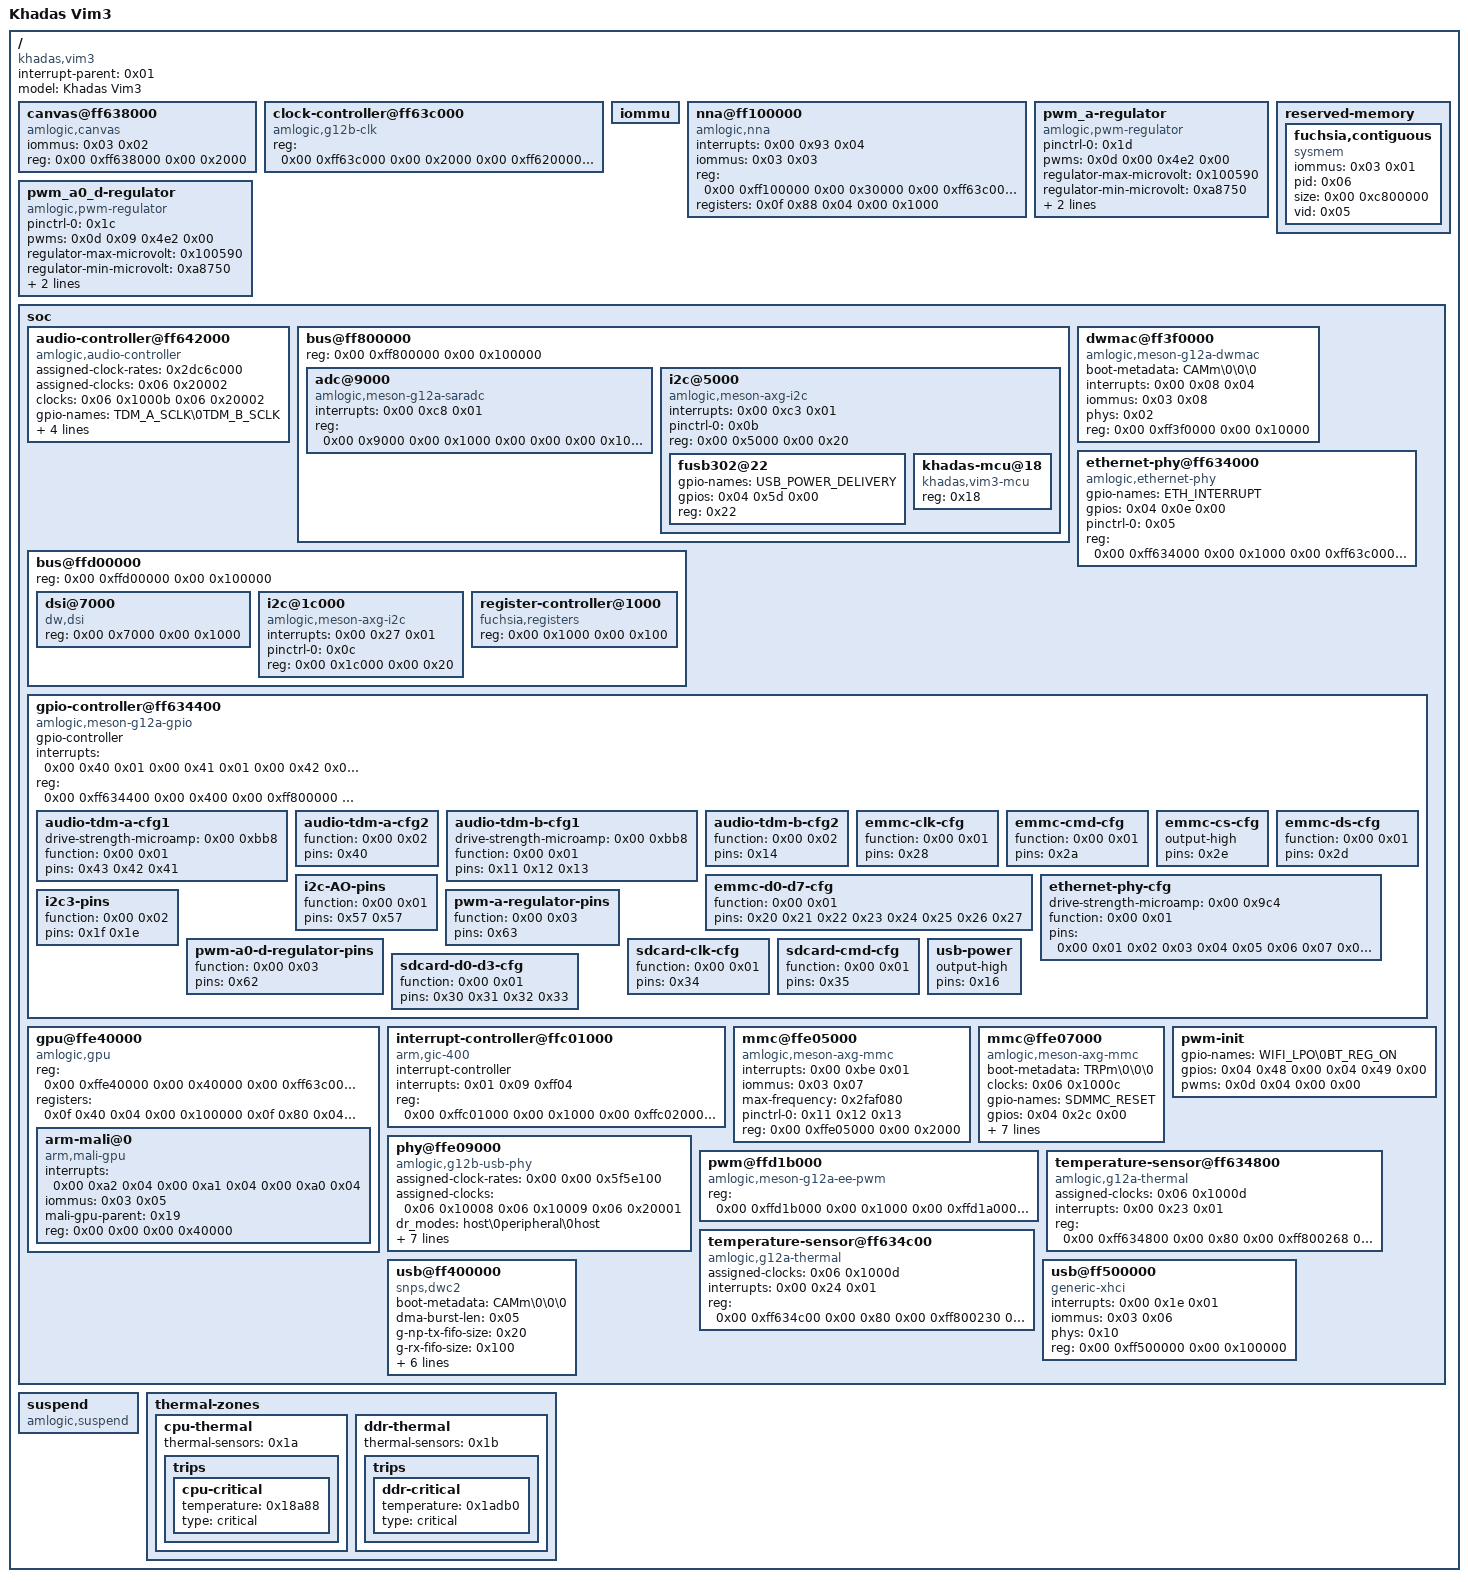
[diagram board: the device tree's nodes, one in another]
/dts-v1/;

/ {
	#address-cells = <0x02>;
	#size-cells = <0x02>;
	compatible = "khadas,vim3\0amlogic,a311d";
	interrupt-parent = <0x01>;
	model = "Khadas Vim3";

	canvas@ff638000 {
		compatible = "amlogic,canvas";
		iommus = <0x03 0x02>;
		reg = <0x00 0xff638000 0x00 0x2000>;
	};

	clock-controller@ff63c000 {
		#clock-cells = <0x01>;
		compatible = "amlogic,g12b-clk";
		phandle = <0x06>;
		reg = <0x00 0xff63c000 0x00 0x2000 0x00 0xff620000 0x00 0x10000 0x00 0xffd18000 0x00 0x1000>;
	};

	iommu {
		#iommu-cells = <0x01>;
		phandle = <0x03>;
	};

	nna@ff100000 {
		compatible = "amlogic,nna";
		interrupts = <0x00 0x93 0x04>;
		iommus = <0x03 0x03>;
		reg = <0x00 0xff100000 0x00 0x30000 0x00 0xff63c000 0x00 0x2000 0x00 0xff800000 0x00 0x1000 0x00 0xff63c000 0x00 0x1000 0x00 0xff000000 0x00 0x100000>;
		registers = <0x0f 0x88 0x04 0x00 0x1000>;
	};

	pwm_a-regulator {
		#regulator-cells = <0x00>;
		compatible = "amlogic,pwm-regulator";
		pinctrl-0 = <0x1d>;
		pwms = <0x0d 0x00 0x4e2 0x00>;
		regulator-max-microvolt = <0x100590>;
		regulator-min-microvolt = <0xa8750>;
		regulator-name = "pwm_vreg_big";
		regulator-step-microvolt = <0x3e8>;
	};

	pwm_a0_d-regulator {
		#regulator-cells = <0x00>;
		compatible = "amlogic,pwm-regulator";
		pinctrl-0 = <0x1c>;
		pwms = <0x0d 0x09 0x4e2 0x00>;
		regulator-max-microvolt = <0x100590>;
		regulator-min-microvolt = <0xa8750>;
		regulator-name = "pwm_vreg_little";
		regulator-step-microvolt = <0x3e8>;
	};

	reserved-memory {
		#address-cells = <0x02>;
		#size-cells = <0x02>;
		ranges;

		fuchsia,contiguous {
			compatible = "sysmem";
			iommus = <0x03 0x01>;
			pid = <0x06>;
			size = <0x00 0xc800000>;
			vid = <0x05>;
		};
	};

	soc {
		#address-cells = <0x02>;
		#size-cells = <0x02>;
		ranges;

		audio-controller@ff642000 {
			assigned-clock-rates = <0x2dc6c000>;
			assigned-clocks = <0x06 0x20002>;
			clock-names = "AUDIO_GATE\0AUDIO_PLL";
			clocks = <0x06 0x1000b 0x06 0x20002>;
			compatible = "amlogic,audio-controller";
			gpio-names = "TDM_A_SCLK\0TDM_B_SCLK";
			gpios = <0x04 0x43 0x00 0x04 0x11 0x00>;
			iommus = <0x03 0x04>;
			pinctrl-0 = <0x07 0x08 0x09 0x0a>;
			reg = <0x00 0xff642000 0x00 0x2000>;
		};

		bus@ff800000 {
			#address-cells = <0x02>;
			#size-cells = <0x02>;
			ranges = <0x00 0x00 0x00 0xff800000 0x00 0x100000>;
			reg = <0x00 0xff800000 0x00 0x100000>;

			adc@9000 {
				compatible = "amlogic,meson-g12a-saradc";
				interrupts = <0x00 0xc8 0x01>;
				reg = <0x00 0x9000 0x00 0x1000 0x00 0x00 0x00 0x100000>;
			};

			i2c@5000 {
				#address-cells = <0x01>;
				#size-cells = <0x00>;
				compatible = "amlogic,meson-axg-i2c";
				interrupts = <0x00 0xc3 0x01>;
				pinctrl-0 = <0x0b>;
				reg = <0x00 0x5000 0x00 0x20>;

				fusb302@22 {
					gpio-names = "USB_POWER_DELIVERY";
					gpios = <0x04 0x5d 0x00>;
					reg = <0x22>;
				};

				khadas-mcu@18 {
					compatible = "khadas,vim3-mcu";
					reg = <0x18>;
				};
			};
		};

		bus@ffd00000 {
			#address-cells = <0x02>;
			#size-cells = <0x02>;
			ranges = <0x00 0x00 0x00 0xffd00000 0x00 0x100000>;
			reg = <0x00 0xffd00000 0x00 0x100000>;

			dsi@7000 {
				compatible = "dw,dsi";
				reg = <0x00 0x7000 0x00 0x1000>;
			};

			i2c@1c000 {
				#address-cells = <0x01>;
				#size-cells = <0x00>;
				compatible = "amlogic,meson-axg-i2c";
				interrupts = <0x00 0x27 0x01>;
				pinctrl-0 = <0x0c>;
				reg = <0x00 0x1c000 0x00 0x20>;
			};

			register-controller@1000 {
				#register-cells = <0x04>;
				compatible = "fuchsia,registers";
				phandle = <0x0f>;
				reg = <0x00 0x1000 0x00 0x100>;
			};
		};

		dwmac@ff3f0000 {
			boot-metadata = "CAMm\0\0\0";
			compatible = "amlogic,meson-g12a-dwmac";
			interrupts = <0x00 0x08 0x04>;
			iommus = <0x03 0x08>;
			phys = <0x02>;
			reg = <0x00 0xff3f0000 0x00 0x10000>;
		};

		ethernet-phy@ff634000 {
			#phy-cells = <0x00>;
			compatible = "amlogic,ethernet-phy";
			gpio-names = "ETH_INTERRUPT";
			gpios = <0x04 0x0e 0x00>;
			phandle = <0x02>;
			pinctrl-0 = <0x05>;
			reg = <0x00 0xff634000 0x00 0x1000 0x00 0xff63c000 0x00 0x2000>;
		};

		gpio-controller@ff634400 {
			#gpio-cells = <0x02>;
			compatible = "amlogic,meson-g12a-gpio";
			gpio-controller;
			interrupts = <0x00 0x40 0x01 0x00 0x41 0x01 0x00 0x42 0x01 0x00 0x43 0x01 0x00 0x44 0x01 0x00 0x45 0x01 0x00 0x46 0x01 0x00 0x47 0x01>;
			phandle = <0x04>;
			reg = <0x00 0xff634400 0x00 0x400 0x00 0xff800000 0x00 0x1000 0x00 0xffd00000 0x00 0x10000>;

			audio-tdm-a-cfg1 {
				drive-strength-microamp = <0x00 0xbb8>;
				function = <0x00 0x01>;
				phandle = <0x07>;
				pins = <0x43 0x42 0x41>;
			};

			audio-tdm-a-cfg2 {
				function = <0x00 0x02>;
				phandle = <0x08>;
				pins = <0x40>;
			};

			audio-tdm-b-cfg1 {
				drive-strength-microamp = <0x00 0xbb8>;
				function = <0x00 0x01>;
				phandle = <0x09>;
				pins = <0x11 0x12 0x13>;
			};

			audio-tdm-b-cfg2 {
				function = <0x00 0x02>;
				phandle = <0x0a>;
				pins = <0x14>;
			};

			emmc-clk-cfg {
				function = <0x00 0x01>;
				phandle = <0x15>;
				pins = <0x28>;
			};

			emmc-cmd-cfg {
				function = <0x00 0x01>;
				phandle = <0x16>;
				pins = <0x2a>;
			};

			emmc-cs-cfg {
				output-high;
				phandle = <0x18>;
				pins = <0x2e>;
			};

			emmc-d0-d7-cfg {
				function = <0x00 0x01>;
				phandle = <0x14>;
				pins = <0x20 0x21 0x22 0x23 0x24 0x25 0x26 0x27>;
			};

			emmc-ds-cfg {
				function = <0x00 0x01>;
				phandle = <0x17>;
				pins = <0x2d>;
			};

			ethernet-phy-cfg {
				drive-strength-microamp = <0x00 0x9c4>;
				function = <0x00 0x01>;
				phandle = <0x05>;
				pins = <0x00 0x01 0x02 0x03 0x04 0x05 0x06 0x07 0x08 0x09 0x0a 0x0b 0x0c 0x0d>;
			};

			i2c-AO-pins {
				function = <0x00 0x01>;
				phandle = <0x0b>;
				pins = <0x57 0x57>;
			};

			i2c3-pins {
				function = <0x00 0x02>;
				phandle = <0x0c>;
				pins = <0x1f 0x1e>;
			};

			pwm-a-regulator-pins {
				function = <0x00 0x03>;
				phandle = <0x1d>;
				pins = <0x63>;
			};

			pwm-a0-d-regulator-pins {
				function = <0x00 0x03>;
				phandle = <0x1c>;
				pins = <0x62>;
			};

			sdcard-clk-cfg {
				function = <0x00 0x01>;
				phandle = <0x12>;
				pins = <0x34>;
			};

			sdcard-cmd-cfg {
				function = <0x00 0x01>;
				phandle = <0x13>;
				pins = <0x35>;
			};

			sdcard-d0-d3-cfg {
				function = <0x00 0x01>;
				phandle = <0x11>;
				pins = <0x30 0x31 0x32 0x33>;
			};

			usb-power {
				output-high;
				phandle = <0x0e>;
				pins = <0x16>;
			};
		};

		gpu@ffe40000 {
			#address-cells = <0x02>;
			#size-cells = <0x02>;
			compatible = "amlogic,gpu";
			phandle = <0x19>;
			ranges = <0x00 0x00 0x00 0xffe40000 0x00 0x40000>;
			reg = <0x00 0xffe40000 0x00 0x40000 0x00 0xff63c000 0x00 0x2000>;
			registers = <0x0f 0x40 0x04 0x00 0x100000 0x0f 0x80 0x04 0x00 0x100000 0x0f 0x48 0x04 0x00 0x4000 0x0f 0x88 0x04 0x00 0x4000>;

			arm-mali@0 {
				compatible = "arm,mali-gpu";
				interrupts = <0x00 0xa2 0x04 0x00 0xa1 0x04 0x00 0xa0 0x04>;
				iommus = <0x03 0x05>;
				mali-gpu-parent = <0x19>;
				reg = <0x00 0x00 0x00 0x40000>;
			};
		};

		interrupt-controller@ffc01000 {
			#address-cells = <0x00>;
			#interrupt-cells = <0x03>;
			compatible = "arm,gic-400";
			interrupt-controller;
			interrupts = <0x01 0x09 0xff04>;
			phandle = <0x01>;
			reg = <0x00 0xffc01000 0x00 0x1000 0x00 0xffc02000 0x00 0x2000 0x00 0xffc04000 0x00 0x2000 0x00 0xffc06000 0x00 0x2000>;
		};

		mmc@ffe05000 {
			compatible = "amlogic,meson-axg-mmc";
			interrupts = <0x00 0xbe 0x01>;
			iommus = <0x03 0x07>;
			max-frequency = <0x2faf080>;
			pinctrl-0 = <0x11 0x12 0x13>;
			reg = <0x00 0xffe05000 0x00 0x2000>;
		};

		mmc@ffe07000 {
			boot-metadata = "TRPm\0\0\0";
			clocks = <0x06 0x1000c>;
			compatible = "amlogic,meson-axg-mmc";
			gpio-names = "SDMMC_RESET";
			gpios = <0x04 0x2c 0x00>;
			interrupts = <0x00 0xbf 0x01>;
			iommus = <0x03 0x06>;
			max-frequency = <0x7270e00>;
			no-mmc-hs400;
			non-removable;
			pinctrl-0 = <0x14 0x15 0x16 0x17 0x18>;
			reg = <0x00 0xffe07000 0x00 0x2000>;
		};

		phy@ffe09000 {
			#phy-cells = <0x00>;
			assigned-clock-rates = <0x00 0x00 0x5f5e100>;
			assigned-clocks = <0x06 0x10008 0x06 0x10009 0x06 0x20001>;
			compatible = "amlogic,g12b-usb-phy";
			dr_modes = "host\0peripheral\0host";
			interrupts = <0x00 0x10 0x01>;
			iommus = <0x03 0x06>;
			phandle = <0x10>;
			pinctrl-0 = <0x0e>;
			reg = <0x00 0xffe09000 0x00 0x2000 0x00 0xff636000 0x00 0x2000 0x00 0xff63a000 0x00 0x2000 0x00 0xff646000 0x00 0x2000>;
			reg-names = "usb-ctrl\0usb2-phy\0usb2-otg-phy\0usb3-phy";
			registers = <0x0f 0x08 0x04 0x00 0x10004 0x0f 0x84 0x04 0x00 0x30000>;
		};

		pwm-init {
			gpio-names = "WIFI_LPO\0BT_REG_ON";
			gpios = <0x04 0x48 0x00 0x04 0x49 0x00>;
			pwms = <0x0d 0x04 0x00 0x00>;
		};

		pwm@ffd1b000 {
			#pwm-cells = <0x03>;
			compatible = "amlogic,meson-g12a-ee-pwm";
			phandle = <0x0d>;
			reg = <0x00 0xffd1b000 0x00 0x1000 0x00 0xffd1a000 0x00 0x1000 0x00 0xffd19000 0x00 0x1000 0x00 0xff807000 0x00 0x1000 0x00 0xff802000 0x00 0x1000>;
		};

		temperature-sensor@ff634800 {
			#thermal-sensor-cells = <0x00>;
			assigned-clocks = <0x06 0x1000d>;
			compatible = "amlogic,g12a-thermal";
			interrupts = <0x00 0x23 0x01>;
			phandle = <0x1a>;
			reg = <0x00 0xff634800 0x00 0x80 0x00 0xff800268 0x00 0x04>;
		};

		temperature-sensor@ff634c00 {
			#thermal-sensor-cells = <0x00>;
			assigned-clocks = <0x06 0x1000d>;
			compatible = "amlogic,g12a-thermal";
			interrupts = <0x00 0x24 0x01>;
			phandle = <0x1b>;
			reg = <0x00 0xff634c00 0x00 0x80 0x00 0xff800230 0x00 0x04>;
		};

		usb@ff400000 {
			boot-metadata = "CAMm\0\0\0";
			compatible = "snps,dwc2";
			dma-burst-len = <0x05>;
			g-np-tx-fifo-size = <0x20>;
			g-rx-fifo-size = <0x100>;
			g-turnaround-time = <0x09>;
			g-tx-fifo-size = <0x80 0x04 0x80 0x10>;
			interrupts = <0x00 0x1f 0x01>;
			iommus = <0x03 0x06>;
			phy-names = "dwc2-phy";
			phys = <0x10>;
			reg = <0x00 0xff400000 0x00 0x100000>;
		};

		usb@ff500000 {
			compatible = "generic-xhci";
			interrupts = <0x00 0x1e 0x01>;
			iommus = <0x03 0x06>;
			phy-names = "xhci-phy";
			phys = <0x10>;
			reg = <0x00 0xff500000 0x00 0x100000>;
		};
	};

	suspend {
		compatible = "amlogic,suspend";
	};

	thermal-zones {

		cpu-thermal {
			thermal-sensors = <0x1a>;

			trips {

				cpu-critical {
					temperature = <0x18a88>;
					type = "critical";
				};
			};
		};

		ddr-thermal {
			thermal-sensors = <0x1b>;

			trips {

				ddr-critical {
					temperature = <0x1adb0>;
					type = "critical";
				};
			};
		};
	};
};
